# STM32H7RSxx register map
File version: 0.2
CPU: CM7 r0p1, little endian, MPU, FPU, 4 interrupt priority bits
Registers are 32-bit, read-write, reset 0x0 unless marked. A register's access mark holds for its fields unless they carry their own. Offsets are from the block's base; [hi:lo] are bit positions; {n}, {i} and the like mark numbered series.

## ETH (part 4 of 4) — Ethernet register block
Base 0x40028000
0xBC4 ETH_MACSPI0R — PTP Source Port Identity 0 Register
  [31:0] SPI0 — Source Port Identity 0 This field indicates bits [31:0] of sourcePortIdentity of PTP node.
0xBC8 ETH_MACSPI1R — PTP Source port identity 1 register
  [31:0] SPI1 — Source Port Identity 1 This field indicates bits [63:32] of sourcePortIdentity of PTP node.
0xBCC ETH_MACSPI2R — PTP Source port identity 2 register
  [15:0] SPI2 — Source Port Identity 2 This field indicates bits [79:64] of sourcePortIdentity of PTP node.
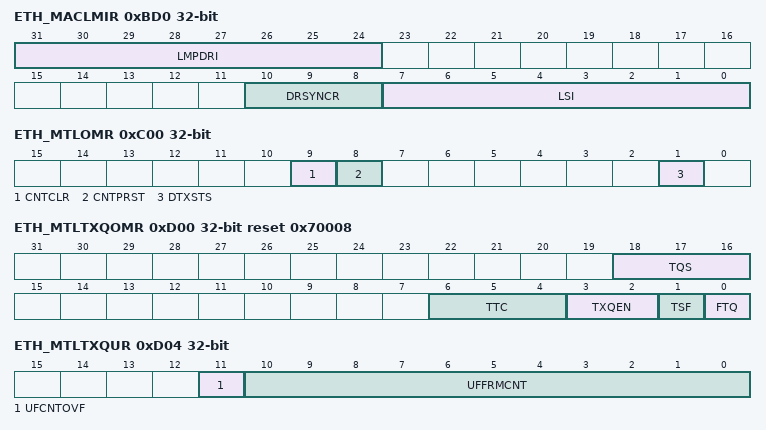
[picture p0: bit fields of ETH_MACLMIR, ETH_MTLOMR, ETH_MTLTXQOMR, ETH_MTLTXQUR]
0xBD0 ETH_MACLMIR — Log message interval register
  [31:24] LMPDRI — Log Min Pdelay_Req Interval This field indicates logMinPdelayReqInterval of PTP node. This is used to schedule the periodic Pdelay request packet transmission. Allowed values are -15 to 15.Negative value must be represented in 2's-complement form. For example, if the required value is -1, the value programmed must be 0xFF.
  [10:8] DRSYNCR — Delay_Req to SYNC Ratio In Slave mode, it is used for controlling frequency of Delay_Req messages transmitted. Others: Reserved, must not be used The master sends this information (logMinDelayReqInterval) in the DelayResp PTP messages to the slave. The reception processes this value from the received DelayResp messages and updates this field accordingly. In the Slave mode, the host must not write/update this register unless it has to override the received value. In Master mode, the sum of this field and logSyncInterval (LSI) field is provided in the logMinDelayReqInterval field of the generated multicast Delay_Resp PTP message.
    0=DelayReq generated for every received SYNC; 1=DelayReq generated every alternate reception of SYNC
  [7:0] LSI — Log Sync Interval This field indicates the periodicity of the automatically generated SYNC message when the PTP node is Master. Allowed values are -15 to 15. Negative value must be represented in 2's-complement form. For example, if the required value is -1, the value programmed must be 0xFF.
0xC00 ETH_MTLOMR — Operating mode Register
  [9] CNTCLR — Counters Reset When this bit is set, all counters are reset. This bit is cleared automatically after 1 clock cycle. If this bit is set along with CNTPRST bit, CNTPRST has precedence.
  [8] CNTPRST — Counters Preset When this bit is set: Tx queue underflow register (ETH_MTLTXQUR) is initialized/preset to 0x7F0. Missed Packet and Overflow Packet counters in Rx queue missed packet and overflow counter register (ETH_MTLRXQMPOCR) is initialized/preset to 0x7F0 This bit is cleared automatically.
  [1] DTXSTS — Drop Transmit Status When this bit is set, the Tx packet status received from the MAC is dropped in the MTL. When this bit is reset, the Tx packet status received from the MAC is forwarded to the application.
0xC20 ETH_MTLISR ro — Interrupt status Register
  [0] Q0IS — Queue interrupt status This bit indicates that an interrupt has been generated by Queue. To reset this bit, read ETH_MTLQICSR register to identify the interrupt cause and clear the source.
0xD00 ETH_MTLTXQOMR access per field reset 0x70008 — Tx queue operating mode Register
  [18:16] TQS rw — Transmit queue size This field indicates the size of the allocated transmit queues in blocks of 256 bytes. Queue size range from 256 bytes (TQS=0b000) to 2048 bytes (TQS=0b111).
  [6:4] TTC rw — Transmit Threshold Control These bits control the threshold level of the MTL Tx queue. The transmission starts when the packet size within the MTL Tx queue is larger than the threshold. In addition, full packets with length less than the threshold are also transmitted. These bits are used only when the TSF bit is reset.
    0=32; 1=64; 2=96; 3=128; 4=192; 5=256; 6=384; 7=512
  [3:2] TXQEN ro — Transmit Queue Enable This field is used to enable/disable the transmit queue . Others: Reserved, must not be used. Note: In multiple Tx queues configuration, all the queues are disabled by default. Enable the Tx queue by programming this field.
    0=Not enabled; 2=Enabled
  [1] TSF rw — Transmit Store and Forward When this bit is set, the transmission starts when a full packet resides in the MTL Tx queue. When this bit is set, the TTC values specified in Bits[6:4] of this register are ignored. This bit should be changed only when the transmission is stopped.
  [0] FTQ rw — Flush Transmit Queue When this bit is set, the Tx queue controller logic is reset to its default values. Therefore, all the data in the Tx queue is lost or flushed. This bit is internally reset when the flushing operation is complete. Until this bit is reset, you should not write to the ETH_MTLTXQOMR register. The data which is already accepted by the MAC transmitter is not flushed. It is scheduled for transmission and results in underflow and runt packet transmission. Note: The flush operation is complete only when the Tx queue is empty and the application has accepted the pending Tx Status of all transmitted packets. To complete this flush operation, the PHY Tx clock (eth_mii_tx_clk) should be active.
0xD04 ETH_MTLTXQUR — Tx queue underflow register
  [11] UFCNTOVF read-clears — Overflow Bit for Underflow Packet Counter This bit is set every time the Tx queue Underflow Packet Counter field overflows, that is, it has crossed the maximum count. In such a scenario, the overflow packet counter is reset to all-zeros and this bit indicates that the rollover happened.
  [10:0] UFFRMCNT read-clears — Underflow Packet Counter This field indicates the number of packets aborted by the controller because of Tx queue Underflow. This counter is incremented each time the MAC aborts outgoing packet because of underflow. The counter is cleared when this register is read.
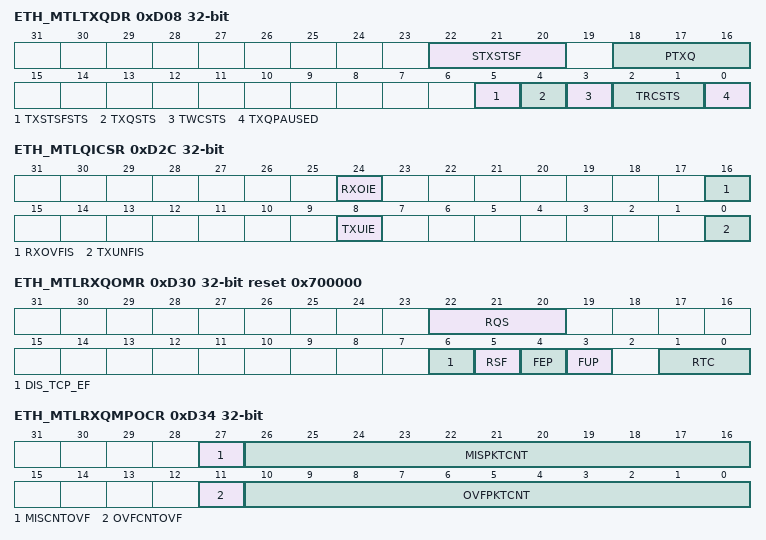
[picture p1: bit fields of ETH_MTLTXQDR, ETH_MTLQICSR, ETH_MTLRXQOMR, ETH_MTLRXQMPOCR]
0xD08 ETH_MTLTXQDR ro — Tx queue debug Register
  [22:20] STXSTSF — Number of Status Words in Tx Status FIFO of Queue This field indicates the current number of status in the Tx Status FIFO of this queue. When the DTXSTS bit of ETH_MTLOMR register is set to 1, this field does not reflect the number of status words in Tx Status FIFO.
  [18:16] PTXQ — Number of Packets in the Transmit Queue This field indicates the current number of packets in the Tx queue. When the DTXSTS bit of Operating mode Register (ETH_MTLOMR) register is set to 1, this field does not reflect the number of packets in the Transmit queue.
  [5] TXSTSFSTS — MTL Tx Status FIFO Full Status When high, this bit indicates that the MTL Tx Status FIFO is full. Therefore, the MTL cannot accept any more packets for transmission.
  [4] TXQSTS — MTL Tx Queue Not Empty Status When this bit is high, it indicates that the MTL Tx queue is not empty and some data is left for transmission.
  [3] TWCSTS — MTL Tx Queue Write Controller Status When high, this bit indicates that the MTL Tx queue Write Controller is active, and it is transferring the data to the Tx queue.
  [2:1] TRCSTS — MTL Tx Queue Read Controller Status This field indicates the state of the Tx Queue Read Controller:
    0=Idle state; 1=Read state (transferring data to the MAC transmitter); 2=Waiting for pending Tx Status from the MAC transmitter; 3=Flushing the Tx queue because of the Packet Abort request from the MAC
  [0] TXQPAUSED — Transmit Queue in Pause When this bit is high and the Rx flow control is enabled, it indicates that the Tx queue is in the Pause condition (in the Full-duplex only mode) because of the following: Reception of the PFC packet for the priorities assigned to the Tx queue when PFC is enabled Reception of 802.3x Pause packet when PFC is disabled
0xD2C ETH_MTLQICSR — Queue interrupt control status Register
  [24] RXOIE — Receive Queue Overflow Interrupt Enable When this bit is set, the Receive Queue Overflow interrupt is enabled. When this bit is reset, the Receive Queue Overflow interrupt is disabled.
  [16] RXOVFIS — Receive Queue Overflow Interrupt Status This bit indicates that the Receive Queue had an overflow while receiving the packet. If a partial packet is transferred to the application, the overflow status is set in RDES3[21]. This bit is cleared when the application writes 1 to this bit.
  [8] TXUIE — Transmit Queue Underflow Interrupt Enable When this bit is set, the Transmit Queue Underflow interrupt is enabled. When this bit is reset, the Transmit Queue Underflow interrupt is disabled.
  [0] TXUNFIS — Transmit Queue Underflow Interrupt Status This bit indicates that the Transmit Queue had an underflow while transmitting the packet. Transmission is suspended and an Underflow Error TDES3[2] is set. This bit is cleared when the application writes 1 to this bit.
0xD30 ETH_MTLRXQOMR access per field reset 0x700000 — Rx queue operating mode register
  [22:20] RQS ro — Receive Queue Size This field is read-only and the configured Rx FIFO size in blocks of 256 bytes is reflected in the reset value. The size of the Queue is (RQS + 1) * 256 bytes.
  [6] DIS_TCP_EF rw — Disable Dropping of TCP/IP Checksum Error Packets When this bit is set, the MAC does not drop the packets which only have the errors detected by the Receive Checksum Offload engine. Such packets have errors only in the encapsulated payload. There are no errors (including FCS error) in the Ethernet packet received by the MAC. When this bit is reset, all error packets are dropped if the FEP bit is reset.
  [5] RSF rw — Receive Queue Store and Forward When this bit is set, the Ethernet peripheral reads a packet from the Rx queue only after the complete packet has been written to it, ignoring the RTC field of this register. When this bit is reset, the Rx queue operates in the Threshold (cut-through) mode, subject to the threshold specified by the RTC field of this register.
  [4] FEP rw — Forward Error Packets When this bit is reset, the Rx queue drops packets with error status (CRC error, receive error, watchdog timeout, or overflow). However, if the start byte (write) pointer of a packet is already transferred to the read controller side (in Threshold mode), the packet is not dropped. When this bit is set, all packets except the runt error packets are forwarded to the application or DMA. If the RSF bit is set and the Rx queue overflows when a partial packet is written, the packet is dropped irrespective of the setting of this bit. However, if the RSF bit is reset and the Rx queue overflows when a partial packet is written, a partial packet may be forwarded to the application or DMA.
  [3] FUP rw — Forward Undersized Good Packets When this bit is set, the Rx queue forwards the undersized good packets (packets with no error and length less than 64 bytes), including pad-bytes and CRC. When this bit is reset, the Rx queue drops all packets of less than 64 bytes, unless a packet is already transferred because of the lower value of Rx Threshold, for example, RTC = 01.
  [1:0] RTC rw — Receive Queue Threshold Control These bits control the threshold level of the MTL Rx queue (in bytes): The received packet is transferred to the application or DMA when the packet size within the MTL Rx queue is larger than the threshold. In addition, full packets with length less than the threshold are automatically transferred. This field is valid only when the RSF bit is zero. This field is ignored when the RSF bit is set to 1.
    0=64; 1=32; 2=96; 3=128
0xD34 ETH_MTLRXQMPOCR — Rx queue missed packet and overflow counter register
  [27] MISCNTOVF read-clears — Missed Packet Counter Overflow Bit When set, this bit indicates that the Rx Queue Missed Packet Counter crossed the maximum limit.
  [26:16] MISPKTCNT read-clears — Missed Packet Counter This field indicates the number of packets missed by the Ethernet peripheral because the application requested to flush the packets for this queue. This counter is reset when this register is read. This counter is incremented by 1 when the DMA discards the packet because of buffer unavailability.
  [11] OVFCNTOVF read-clears — Overflow Counter Overflow Bit When set, this bit indicates that the Rx Queue Overflow Packet Counter field crossed the maximum limit.
  [10:0] OVFPKTCNT read-clears — Overflow Packet Counter This field indicates the number of packets discarded by the Ethernet peripheral because of Receive queue overflow. This counter is incremented each time the Ethernet peripheral discards an incoming packet because of overflow. This counter is reset when this register is read.
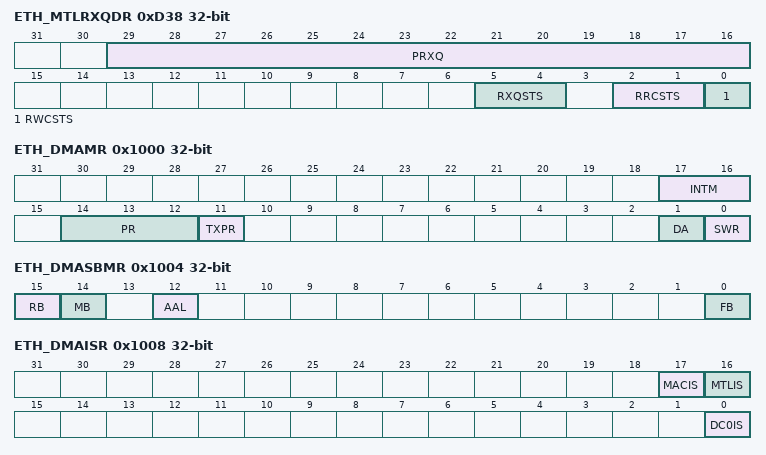
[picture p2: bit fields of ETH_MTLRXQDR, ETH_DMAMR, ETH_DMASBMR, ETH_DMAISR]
0xD38 ETH_MTLRXQDR ro — Rx queue debug register
  [29:16] PRXQ — Number of Packets in Receive Queue This field indicates the current number of packets in the Rx queue. The theoretical maximum value for this field is 256Kbyte/16bytes = 16K Packets, that is, Max_Queue_Size/Min_Packet_Size.
  [5:4] RXQSTS — MTL Rx Queue Fill-Level Status This field gives the status of the fill-level of the Rx queue:
    0=Rx queue empty; 1=Rx queue fill-level below flow-control deactivate threshold; 2=Rx queue fill-level above flow-control activate threshold; 3=Rx queue full
  [2:1] RRCSTS — MTL Rx Queue Read Controller State This field gives the state of the Rx queue Read controller:
    0=Idle state; 1=Reading packet data; 2=Reading packet status (or timestamp); 3=Flushing the packet data and status
  [0] RWCSTS — MTL Rx Queue Write Controller Active Status When high, this bit indicates that the MTL Rx queue Write controller is active, and it is transferring a received packet to the Rx queue.
0x1000 ETH_DMAMR — DMA mode register
  [17:16] INTM — Interrupt Mode This field defines the interrupt mode of the Ethernet peripheral. The behavior of the interrupt signal and of the RI/TI bits in the ETH_DMACSR register changes depending on the INTM value (refer to Table 535: Transfer complete interrupt behavior).
  [14:12] PR — Priority ratio These bits control the priority ratio in weighted round-robin arbitration between the Rx DMA and Tx DMA. These bits are valid only when the DA bit is reset. The priority ratio is Rx:Tx or Tx:Rx depending on whether the TXPR bit is reset or set.
    {v}=The priority ratio is {v+1}:1 (v=0..7)
  [11] TXPR — Transmit priority When set, this bit indicates that the Tx DMA has higher priority than the Rx DMA during arbitration for the system-side bus.
  [1] DA — DMA Tx or Rx Arbitration Scheme This bit specifies the arbitration scheme between the Transmit and Receive paths of all channels: The priority between the paths is according to the priority specified in Bits[14:12] and the priority weight is specified in the TXPR bit. The Tx path has priority over the Rx path when the TXPR bit is set. Otherwise, the Rx path has priority over the Tx path.
    0=Weighted Round-Robin with Rx:Tx or Tx:Rx; 1=Fixed priority
  [0] SWR — Software Reset When this bit is set, the MAC and the DMA controller reset the logic and all internal registers of the DMA, MTL, and MAC. This bit is automatically cleared after the reset operation is complete in all clock domains. Before reprogramming any register, a value of zero should be read in this bit. Note: The reset operation is complete only when all resets in all active clock domains are deasserted. Therefore, it is essential that all PHY inputs clocks (applicable for the selected PHY interface) are present for software reset completion. The time to complete the software reset operation depends on the frequency of the slowest active clock.
0x1004 ETH_DMASBMR access per field — System bus mode register
  [15] RB ro — Rebuild INCRx Burst When this bit is set high and the AHB master gets SPLIT, RETRY, or Early Burst Termination (EBT) response, the AHB master interface rebuilds the pending beats of any initiated burst transfer with INCRx and SINGLE transfers. By default, the AHB master interface rebuilds pending beats of an EBT with an unspecified (INCR) burst.
  [14] MB ro — Mixed Burst When this bit is set high and the FB bit is low, the AHB master performs undefined bursts transfers (INCR) for burst length of 16 or more. For burst length of 16 or less, the AHB master performs fixed burst transfers (INCRx and SINGLE).
  [12] AAL rw — Address-Aligned Beats When this bit is set to 1, the master performs address-aligned burst transfers on Read and Write channels.
  [0] FB rw — Fixed Burst Length When this bit is set to 1, the AHB master will initiate burst transfers of specified length (INCRx or SINGLE). When this bit is set to 0, the AHB master will initiate transfers of unspecified length (INCR) or SINGLE transfers.
0x1008 ETH_DMAISR ro — Interrupt status register
  [17] MACIS — MAC Interrupt Status This bit indicates an interrupt event in the MAC. To reset this bit to 1'b0, the software must read the corresponding register in the MAC to get the exact cause of the interrupt and clear its source.
  [16] MTLIS — MTL Interrupt Status This bit indicates an interrupt event in the MTL. To reset this bit to 1'b0, the software must read the corresponding register in the MTL to get the exact cause of the interrupt and clear its source.
  [0] DC0IS — DMA Channel Interrupt Status This bit indicates an interrupt event in DMA Channel. To reset this bit to 0, the software must read the corresponding register in DMA Channel to get the exact cause of the interrupt and clear its source.
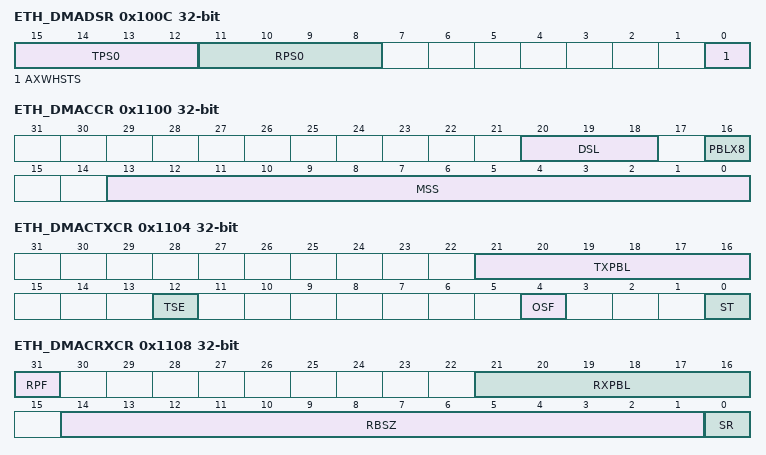
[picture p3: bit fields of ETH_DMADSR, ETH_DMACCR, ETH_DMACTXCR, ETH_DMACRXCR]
0x100C ETH_DMADSR ro — Debug status register
  [15:12] TPS0 — DMA Channel Transmit Process State This field indicates the Tx DMA FSM state for Channel: The MSB of this field always returns 0. This field does not generate an interrupt.
    0=Stopped (Reset or Stop Transmit Command issued); 1=Running (Fetching Tx Transfer Descriptor); 2=Running (Waiting for status); 3=Running (Reading Data from system memory buffer and queuing it to the Tx buffer (Tx FIFO)); 4=Timestamp write state; 5=Reserved for future use; 6=Suspended (Tx Descriptor Unavailable or Tx Buffer Underflow); 7=Running (Closing Tx Descriptor)
  [11:8] RPS0 — DMA Channel Receive Process State This field indicates the Rx DMA FSM state for Channel: The MSB of this field always returns 0. This field does not generate an interrupt.
    0=Stopped (Reset or Stop Receive Command issued); 1=Running (Fetching Rx Transfer Descriptor); 2=Reserved for future use; 3=Running (Waiting for Rx packet); 4=Suspended (Rx Descriptor Unavailable); 5=Running (Closing the Rx Descriptor); 6=Timestamp write state; 7=Running (Transferring the received packet data from the Rx buffer to the system memory)
  [0] AXWHSTS — AHB Master Write Channel When high, this bit indicates that the write channel of the AHB master FMSs are in non-idle state.
0x1100 ETH_DMACCR — Channel control register
  [20:18] DSL — Descriptor Skip Length This bit specifies the 32-bit word number to skip between two unchained descriptors. The address skipping starts from the end of the current descriptor to the start of the next descriptor. When the DSL value is equal to zero, the DMA takes the descriptor table as contiguous.
  [16] PBLX8 — 8xPBL mode When this bit is set, the PBL value programmed in Bits[21:16] in Channel transmit control register (ETH_DMACTXCR) is multiplied eight times. Therefore, the DMA transfers the data in 8, 16, 32, 64, 128, and 256 beats depending on the PBL value.
  [13:0] MSS — Maximum Segment Size This field specifies the maximum segment size that should be used while segmenting the packet. This field is valid only if the TSE bit of Channel transmit control register (ETH_DMACTXCR) is set. The value programmed in this field must be more than the configured Data width in bytes. It is recommended to use a MSS value of 64 bytes or more.
0x1104 ETH_DMACTXCR — Channel transmit control register
  [21:16] TXPBL — Transmit Programmable Burst Length These bits indicate the maximum number of beats to be transferred in one DMA data transfer. This is the maximum value that is used in a single block Read or Write. The DMA always attempts to burst as specified in PBL each time it starts a burst transfer on the application bus. You can program PBL with any of the following values: 1, 2, 4, 8, 16, or 32. Any other value results in undefined behavior. To transfer more than 32 beats, perform the following steps: Set the PBLx8 mode in ETH_DMACCR. Set the TXPBL[5:0]. Note: The maximum value of TXPBL must be less than or equal to half the Tx Queue size (TQS field of Tx queue operating mode Register (ETH_MTLTXQOMR)) in terms of beats. This is required so that the Tx Queue has space to store at least another Tx PBL worth of data while the MTL Tx Queue Controller is transferring data to MAC. The total locations in Tx Queue of size 2048 bytes is 512, TXPBL and 8xPBL needs to be programmed to less than or equal to 512/2.
  [12] TSE — TCP Segmentation Enabled When this bit is set, the DMA performs the TCP segmentation for packets in Channel i. The TCP segmentation is done only for those packets for which the TSE bit (TDES0[19]) is set in the Tx Normal descriptor. When this bit is set, the TxPBL value must be greater than or equal to 4.
  [4] OSF — Operate on Second Packet When this bit is set, it instructs the DMA to process the second packet of the Transmit data even before the status for the first packet is obtained.
  [0] ST — Start or Stop Transmission Command When this bit is set, transmission is placed in the Running state. The DMA checks the Transmit list at the current position for a packet to be transmitted. The DMA tries to acquire descriptor from either of the following positions: The current position in the list: this is the base address of the Transmit list set by the ETH_DMACTXDLAR register. The position at which the transmission was previously stopped If the DMA does not own the current descriptor, the transmission enters the Suspended state and the TBU bit of the ETH_DMACSR is set. The Start Transmission command is effective only when the transmission is stopped. If the command is issued before setting the ETH_DMACTXDLAR register, the DMA behavior is unpredictable. When this bit is reset, the transmission process is placed in the Stopped state after completing the transmission of the current packet. The Next Descriptor position in the Transmit list is saved, and it becomes the current position when the transmission is restarted. To change the list address, you need to program ETH_DMACTXDLAR register with a new value when this bit is reset. The new value is considered when this bit is set again. The stop transmission command is effective only when the transmission of the current packet is complete or the transmission is in the Suspended state.
0x1108 ETH_DMACRXCR — Channel receive control register
  [31] RPF — DMA Rx Channel Packet Flush When this bit is set to 1, the Ethernet peripheral automatically flushes the packet from the Rx queues destined to DMA Rx Channel when the DMA Rx Channel is stopped after a system bus error has occurred. When this bit remains set and the DMA is re-started by the software driver, the packets residing in the Rx Queues that were received when this RxDMA was stopped, are flushed out. The packets that are received by the MAC after the RxDMA is re-started are routed to the RxDMA. The flushing happens on the Read side of the Rx queue. When this bit is set to 0 the Ethernet peripheral does not flush the packet in the Rx queue destined to DMA Rx Channel after the DMA is stopped due to a system bus error. This might cause head-of-line blocking in the corresponding RxQueue. Note: The stopping of packet flow from a Rx DMA Channel to the application by setting RPF works only when there is one-to-one mapping of Rx Queue to Rx DMA channels. In Dynamic mapping mode, setting RPF bit in ETH_DMACRXCR register might flush packets from unintended Rx Queues which are destined to the stopped Rx DMA Channel.
  [21:16] RXPBL — Receive Programmable Burst Length These bits indicate the maximum number of beats to be transferred in one DMA data transfer. This is the maximum value that is used in a single block Read or Write. The DMA always attempts to burst as specified in PBL each time it starts a burst transfer on the application bus. You can program PBL with any of the following values: 1, 2, 4, 8, 16, or 32. Any other value results in undefined behavior. To transfer more than 32 beats, perform the following steps: Set the PBLx8 mode in the ETH_DMACCR. Set the RXPBL[5:0]. Note: The maximum value of RXPBL must be less than or equal to half the Rx Queue size (RQS field of Rx queue operating mode register (ETH_MTLRXQOMR)) in terms of beats. This is required so that the Rx Queue has space to store at least another Rx PBL worth of data while the MTL Rx Queue Controller is transferring data to MAC.The total locations in Rx Queue of size 2048 bytes is 512, RXPBL and 8xPBL needs to be programmed to less than or equal to 512/2.
  [14:1] RBSZ — Receive Buffer size This field indicates the size of the Rx buffers specified in bytes. The maximum buffer size is limited to 16 Kbytes. Note: The buffer size must be a multiple of 4. This is required even if the value of buffer address pointer is not aligned to bus width. If the buffer size is not a multiple of 4, it may result into an undefined behavior. Note: The LSB bits (1:0) are ignored and the DMA internally takes the LSB bits as all-zero. Therefore, these LSB bits are read-only (RO).
  [0] SR — Start or Stop Receive When this bit is set, the DMA tries to acquire the descriptor from the Receive list and processes the incoming packets. The DMA tries to acquire descriptor from either of the following positions: The current position in the list: this is the address set by the Channel Rx descriptor list address register (ETH_DMACRXDLAR). The position at which the Rx process was previously stopped If the DMA does not own the current descriptor, the reception is suspended and the RBU bit of the ETH_DMACSR is set. The Start Receive command is effective only when the reception is stopped. If the command is issued before setting the Channel Rx descriptor list address register (ETH_DMACRXDLAR), the DMA behavior is unpredictable. When this bit is reset, the Rx DMA operation is stopped after the transfer of the current packet. The next descriptor position in the Receive list is saved, and it becomes the current position after the Rx process is restarted. The Stop Receive command is effective only when the Rx process is in the Running (waiting for Rx packet) or Suspended state.
0x1114 ETH_DMACTXDLAR — Channel Tx descriptor list address register
  [31:0] TDESLA — Start of Transmit List This field contains the base address of the first descriptor in the Transmit descriptor list. The DMA ignores the LSB bits (1:0) for 32-bit bus width and internally takes these bits as all-zero. Therefore, these LSB bits are read-only (RO).
0x111C ETH_DMACRXDLAR — Channel Rx descriptor list address register
  [31:0] RDESLA — Start of Receive List This field contains the base address of the first descriptor in the Rx Descriptor list. The DMA ignores the LSB bits (1:0) for 32-bit bus width and internally takes these bits as all-zero. Therefore, these LSB bits are read-only (RO).
0x1120 ETH_DMACTXDTPR — Channel Tx descriptor tail pointer register
  [31:0] TDT — Transmit Descriptor Tail Pointer This field contains the tail pointer for the Tx descriptor ring. The software writes the tail pointer to add more descriptors to the Tx channel. The hardware tries to transmit all packets referenced by the descriptors between the head and the tail pointer registers.
0x1128 ETH_DMACRXDTPR — Channel Rx descriptor tail pointer register
  [31:0] RDT — Receive Descriptor Tail Pointer This field contains the tail pointer for the Rx descriptor ring. The software writes the tail pointer to add more descriptors to the Rx channel. The hardware tries to write all received packets to the descriptors referenced between the head and the tail pointer registers.
0x112C ETH_DMACTXRLR — Channel Tx descriptor ring length register
  [9:0] TDRL — Transmit Descriptor Ring Length This field sets the maximum number of Tx descriptors in the circular descriptor ring. The maximum number of descriptors is limited to 1K descriptors. It is recommended to put a minimum ring descriptor length of 4. For example, you can program any value up to 0x3FF in this field. This field is 10 bits wide, if you program 0x3FF, you can have 1024 descriptors. If you want to have 10 descriptors, program it to a value of 0x9.
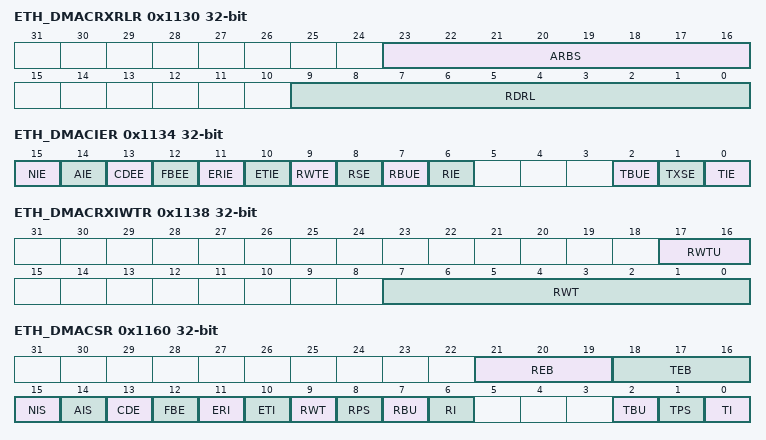
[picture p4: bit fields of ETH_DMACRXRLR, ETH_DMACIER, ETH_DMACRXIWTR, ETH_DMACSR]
0x1130 ETH_DMACRXRLR — Channel Rx descriptor ring length register
  [23:16] ARBS — Alternate Receive Buffer Size Indicates size in bytes for Buffer 1 when ARBS[7:0] is programmed to a non-zero value. When ARBS[7:0] = 0, Rx Buffer1 and Rx Buffer2 sizes are based on RBSZ[13:0] field of Channel receive control register (ETH_DMACRXCR).
  [9:0] RDRL — Receive Descriptor Ring Length This register sets the maximum number of Rx descriptors in the circular descriptor ring. The maximum number of descriptors is limited to 1K descriptors. For example, you can program any value up to 0x3FF in this field. This field is 10-bit wide. If you program 0x3FF, you can have 1024 descriptors. If you want to have 10 descriptors, program it to a value of 0x9.
0x1134 ETH_DMACIER — Channel interrupt enable register
  [15] NIE — Normal Interrupt Summary Enable When this bit is set, the normal interrupt summary is enabled. This bit enables the following interrupts in the Channel status register (ETH_DMACSR): Bit 0: Transmit Interrupt Bit 2: Transmit Buffer Unavailable Bit 6: Receive Interrupt Bit 11: Early Receive Interrupt When this bit is reset, the normal interrupt summary is disabled.
  [14] AIE — Abnormal Interrupt Summary Enable When this bit is set, the abnormal interrupt summary is enabled. This bit enables the following interrupts in the Channel status register (ETH_DMACSR): Bit 1: Transmit Process Stopped Bit 7: Rx Buffer Unavailable Bit 8: Receive Process Stopped Bit 9: Receive Watchdog Timeout Bit 10: Early Transmit Interrupt Bit 12: Fatal Bus Error When this bit is reset, the abnormal interrupt summary is disabled.
  [13] CDEE — Context Descriptor Error Enable When this bit is set along with the AIE bit, the Context Descriptor error interrupt is enabled. When this bit is reset, the Context Descriptor error interrupt is disabled.
  [12] FBEE — Fatal Bus Error Enable When this bit is set along with the AIE bit, the Fatal Bus error interrupt is enabled. When this bit is reset, the Fatal Bus Error error interrupt is disabled.
  [11] ERIE — Early Receive Interrupt Enable When this bit is set along with the NIE bit, the Early Receive interrupt is enabled. When this bit is reset, the Early Receive interrupt is disabled.
  [10] ETIE — Early Transmit Interrupt Enable When this bit is set along with the AIE bit, the Early Transmit interrupt is enabled. When this bit is reset, the Early Transmit interrupt is disabled.
  [9] RWTE — Receive Watchdog Timeout Enable When this bit is set along with the AIE bit, the Receive Watchdog Timeout interrupt is enabled. When this bit is reset, the Receive Watchdog Timeout interrupt is disabled.
  [8] RSE — Receive Stopped Enable When this bit is set along with the AIE bit, the Receive Stopped Interrupt is enabled. When this bit is reset, the Receive Stopped interrupt is disabled.
  [7] RBUE — Receive Buffer Unavailable Enable When this bit is set along with the AIE bit, the Receive Buffer Unavailable interrupt is enabled. When this bit is reset, the Receive Buffer Unavailable interrupt is disabled.
  [6] RIE — Receive Interrupt Enable When this bit is set along with the NIE bit, the Receive Interrupt is enabled. When this bit is reset, the Receive Interrupt is disabled.
  [2] TBUE — Transmit Buffer Unavailable Enable When this bit is set along with the NIE bit, the Transmit Buffer Unavailable interrupt is enabled. When this bit is reset, the Transmit Buffer Unavailable interrupt is disabled.
  [1] TXSE — Transmit Stopped Enable When this bit is set along with the AIE bit, the Transmission Stopped interrupt is enabled. When this bit is reset, the Transmission Stopped interrupt is disabled.
  [0] TIE — Transmit Interrupt Enable When this bit is set along with the NIE bit, the Transmit Interrupt is enabled. When this bit is reset, the Transmit Interrupt is disabled.
0x1138 ETH_DMACRXIWTR — Channel Rx interrupt watchdog timer register
  [17:16] RWTU — Receive Interrupt Watchdog Timer Count Units This field indicates the number of system clock cycles corresponding to one unit in RWT[7:0] field. For example, when RWT[7:0] = 2 and RWTU[1:0] = 1, the watchdog timer is set for 2 * 512 = 1024 system clock cycles.
    0=256; 1=512; 2=1024; 3=2048
  [7:0] RWT — Receive Interrupt Watchdog Timer Count This field indicates the number of system clock cycles, multiplied by factor indicated in RWTU field, for which the watchdog timer is set. The watchdog timer is triggered with the programmed value after the Rx DMA completes the transfer of a packet for which the RI bit is not set in the ETH_DMACSR, because of the setting of Interrupt Enable bit in the corresponding descriptor RDES3[30]. When the watchdog timer runs out, the RI bit is set and the timer is stopped. The watchdog timer is reset when the RI bit is set high because of automatic setting of RI as per the Interrupt Enable bit RDES3[30] of any received packet.
0x1144 ETH_DMACCATXDR ro — Channel current application transmit descriptor register
  [31:0] CURTDESAPTR — Application Transmit Descriptor Address Pointer The DMA updates this pointer during Tx operation. This pointer is cleared on reset.
0x114C ETH_DMACCARXDR ro — Channel current application receive descriptor register
  [31:0] CURRDESAPTR — Application Receive Descriptor Address Pointer The DMA updates this pointer during Rx operation. This pointer is cleared on reset.
0x1154 ETH_DMACCATXBR ro — Channel current application transmit buffer register
  [31:0] CURTBUFAPTR — Application Transmit Buffer Address Pointer The DMA updates this pointer during Tx operation. This pointer is cleared on reset.
0x115C ETH_DMACCARXBR ro — Channel current application receive buffer register
  [31:0] CURRBUFAPTR — Application Receive Buffer Address Pointer The DMA updates this pointer during Rx operation. This pointer is cleared on reset.
0x1160 ETH_DMACSR access per field — Channel status register
  [21:19] REB ro — Rx DMA Error Bits This field indicates the type of error that caused a Bus Error. For example, error response on the AHB interface. Bit [2]: Error during data transfer by Rx DMA when 1, no Error during data transfer by Rx DMA when 0. Bit[1]: Error during descriptor access when 1, Error during data buffer access when 0 Bit[0]: Error during read transfer when 1, Error during write transfer when 0 This field is valid only when the FBE bit is set. This field does not generate an interrupt.
  [18:16] TEB ro — Tx DMA Error Bits This field indicates the type of error that caused a Bus Error. For example, error response on the AHB interface. Bit[2]: Error during data transfer by Tx DMA when 1, no Error during data transfer by Tx DMA when 0 Bit[1]: Error during descriptor access when 1, Error during data buffer access when 0 Bit[0]: Error during read transfer when 1, Error during write transfer when 0 This field is valid only when the FBE bit is set. This field does not generate an interrupt.
  [15] NIS rw — Normal Interrupt Summary Normal Interrupt Summary bit value is the logical OR of the following bits when the corresponding interrupt bits are enabled in the ETH_DMACIER register: Bit 0: Transmit Interrupt Bit 2: Transmit Buffer Unavailable Bit 6: Receive Interrupt Bit 11: Early Receive Interrupt Only unmasked bits (interrupts for which interrupt enable is set in ETH_DMACIER register) affect the Normal Interrupt Summary bit. This is a sticky bit. You must clear this bit (by writing 1 to this bit) each time a corresponding bit which causes NIS to be set is cleared.
  [14] AIS rw — Abnormal Interrupt Summary Abnormal Interrupt Summary bit value is the logical OR of the following when the corresponding interrupt bits are enabled in the ETH_DMACIER register: Bit 1: Transmit Process Stopped Bit 7: Receive Buffer Unavailable Bit 8: Receive Process Stopped Bit 10: Early Transmit Interrupt Bit 12: Fatal Bus Error Bit 13: Context Descriptor Error Only unmasked bits affect the Abnormal Interrupt Summary bit. This is a sticky bit. You must clear this bit (by writing 1 to this bit) each time a corresponding bit, which causes AIS to be set, is cleared.
  [13] CDE rw — Context Descriptor Error This bit indicates that the DMA Tx/Rx engine received a descriptor error, which indicates invalid context in the middle of packet flow (intermediate descriptor) or all one‘s descriptor in Tx case and on Rx side it indicates DMA has read a descriptor with either of the buffer address as ones which is considered to be invalid.
  [12] FBE rw — Fatal Bus Error This bit indicates that a bus error occurred (as described in the EB field). When this bit is set, the corresponding DMA channel engine disables all bus accesses.
  [11] ERI rw — Early Receive Interrupt This bit indicates that the DMA filled the first data buffer of the packet.The RI bit of this register automatically clears this bit.
  [10] ETI rw — Early Transmit Interrupt This bit indicates that the packet to be transmitted is fully transferred to the MTL Tx FIFO.
  [9] RWT rw — Receive Watchdog Timeout This bit is asserted when a packet with length greater than 2,048 bytes (10,240 bytes when Jumbo Packet mode is enabled) is received.
  [8] RPS rw — Receive Process Stopped This bit is asserted when the Rx process enters the Stopped state.
  [7] RBU rw — Receive Buffer Unavailable This bit indicates that the application owns the next descriptor in the Receive list, and the DMA cannot acquire it. The Rx process is suspended. To resume processing Rx descriptors, the application should change the ownership of the descriptor and issue a Receive Poll Demand command. If this command is not issued, the Rx process resumes when the next recognized incoming packet is received. In ring mode, the application should advance the Receive Descriptor Tail Pointer register of a channel. This bit is set only when the DMA owns the previous Rx descriptor.
  [6] RI rw — Receive Interrupt This bit indicates that the packet reception is complete. When packet reception is complete, Bit 31 of RDES1 is reset in the last descriptor, and the specific packet status information is updated in the descriptor. The reception remains in the Running state.
  [2] TBU rw — Transmit Buffer Unavailable This bit indicates that the application owns the next descriptor in the Transmit list, and the DMA cannot acquire it. Transmission is suspended. The TPSi field of the Debug status register (ETH_DMADSR) register explains the Transmit Process state transitions. To resume processing the Transmit descriptors, the application should do the following: 1. Change the ownership of the descriptor by setting Bit 31 of TDES3. 2. Issue a Transmit Poll Demand command. For ring mode, the application should advance the Transmit Descriptor Tail Pointer register of a channel.
  [1] TPS rw — Transmit Process Stopped This bit is set when the transmission is stopped.
  [0] TI rw — Transmit Interrupt This bit indicates that the packet transmission is complete. When transmission is complete, Bit 31 of TDES3 is reset in the last descriptor, and the specific packet status information is updated in the descriptor.
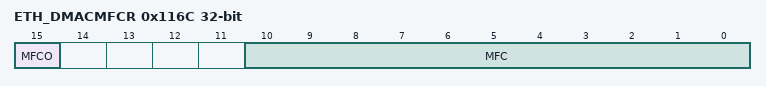
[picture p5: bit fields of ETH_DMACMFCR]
0x116C ETH_DMACMFCR — Channel missed frame count register
  [15] MFCO read-clears — Overflow status of the MFC Counter When this bit is set then the MFC counter does not get incremented further. The bit gets cleared when this register is read.
  [10:0] MFC read-clears — Dropped Packet Counters This counter indicates the number of packet counters that are dropped by the DMA either because of bus error or because of programing RPF field in Channel receive control register (ETH_DMACRXCR). The counter gets cleared when this register is read.
